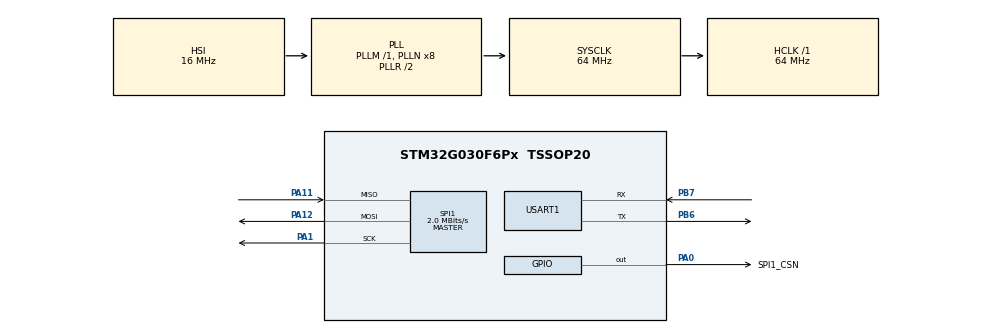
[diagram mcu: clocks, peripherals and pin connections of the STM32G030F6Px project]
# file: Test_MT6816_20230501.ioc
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Mcu.Family=STM32G0
Mcu.Name=STM32G030F6Px
Mcu.Package=TSSOP20
PA0.GPIO_Label=SPI1_CSN
PA0.Signal=GPIO_Output
PA1.Mode=Full_Duplex_Master
PA1.Signal=SPI1_SCK
PA11\ [PA9].Mode=Full_Duplex_Master
PA11\ [PA9].Signal=SPI1_MISO
PA12\ [PA10].Mode=Full_Duplex_Master
PA12\ [PA10].Signal=SPI1_MOSI
PA13.Mode=Serial_Wire
PA13.Signal=SYS_SWDIO
PA14-BOOT0.Mode=Serial_Wire
PA14-BOOT0.Signal=SYS_SWCLK
PA14-BOOT0__PA15.StandardMode=true
PB0__PB1__PB2__PA8.StandardMode=true
PB3__PB4__PB5__PB6.StandardMode=true
PB6.Mode=Asynchronous
PB6.Signal=USART1_TX
PB7.Mode=Asynchronous
PB7.Signal=USART1_RX
PB7__PB8.StandardMode=true
PC14-OSC32_IN\ (PC14)__PB9.StandardMode=true
ProjectManager.HeapSize=0x200
ProjectManager.StackSize=0x400
ProjectManager.TargetToolchain=MDK-ARM V5.32
RCC.ADCFreq_Value=64000000
RCC.AHBFreq_Value=64000000
RCC.CortexFreq_Value=64000000
RCC.EXTERNAL_CLOCK_VALUE=12288000
RCC.HCLKFreq_Value=64000000
RCC.HSE_VALUE=8000000
RCC.HSI_VALUE=16000000
RCC.LSE_VALUE=32768
RCC.SYSCLKFreq_VALUE=64000000
RCC.SYSCLKSource=RCC_SYSCLKSOURCE_PLLCLK
RCC.VCOOutputFreq_Value=128000000
SPI1.BaudRatePrescaler=SPI_BAUDRATEPRESCALER_32
SPI1.CLKPhase=SPI_PHASE_2EDGE
SPI1.CLKPolarity=SPI_POLARITY_HIGH
SPI1.CalculateBaudRate=2.0 MBits/s
SPI1.DataSize=SPI_DATASIZE_16BIT
SPI1.Direction=SPI_DIRECTION_2LINES
SPI1.Mode=SPI_MODE_MASTER
SPI1.VirtualType=VM_MASTER
TIM17.Period=999
TIM17.Prescaler=63
USART1.VirtualMode-Asynchronous=VM_ASYNC
VP_TIM17_VS_ClockSourceINT.Mode=Enable_Timer
board=custom

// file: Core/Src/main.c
/* USER CODE BEGIN Header */
/**
  ******************************************************************************
  * @file           : main.c
  * @brief          : Main program body
  ******************************************************************************
  * @attention
  *
  * Copyright (c) 2023 STMicroelectronics.
  * All rights reserved.
  *
  * This software is licensed under terms that can be found in the LICENSE file
  * in the root directory of this software component.
  * If no LICENSE file comes with this software, it is provided AS-IS.
  *
  ******************************************************************************
  */
/* USER CODE END Header */
#include "main.h"
#include "spi.h"
#include "tim.h"
#include "usart.h"
#include "gpio.h"

/* USER CODE BEGIN Includes */
#include "magnetic_sensor.h"
/* USER CODE END Includes */

void SystemClock_Config(void);

int main(void)
{
  /* USER CODE BEGIN 1 */
	Magnetic_Sensor* MS;

  /* USER CODE END 1 */

  /* MCU Configuration--------------------------------------------------------*/

  /* Reset of all peripherals, Initializes the Flash interface and the Systick. */
  HAL_Init();

  /* Configure the system clock */
  SystemClock_Config();

  /* Initialize all configured peripherals */
  MX_GPIO_Init();
  MX_SPI1_Init();
  MX_USART1_UART_Init();
  MX_TIM17_Init();
  /* USER CODE BEGIN 2 */
	MS = new_Magnetic_Sensor(SPI1, GPIOA, LL_GPIO_PIN_0);
	LL_TIM_EnableCounter(TIM17);
  /* USER CODE END 2 */

  /* Infinite loop */
  while (1)
  {

    /* USER CODE BEGIN 3 */
		MS->get(MS);
		printf("%4x %d %d\r\n", (uint16_t)MS->angle, MS->pc_flag, MS->no_mag_flag);
    HAL_Delay(100);
  }
  /* USER CODE END 3 */
}

void SystemClock_Config(void)
{
  RCC_OscInitTypeDef RCC_OscInitStruct = {0};
  RCC_ClkInitTypeDef RCC_ClkInitStruct = {0};

  /** Configure the main internal regulator output voltage
  */
  HAL_PWREx_ControlVoltageScaling(PWR_REGULATOR_VOLTAGE_SCALE1);

  /** Initializes the RCC Oscillators according to the specified parameters
  * in the RCC_OscInitTypeDef structure.
  */
  RCC_OscInitStruct.OscillatorType = RCC_OSCILLATORTYPE_HSI;
  RCC_OscInitStruct.HSIState = RCC_HSI_ON;
  RCC_OscInitStruct.HSIDiv = RCC_HSI_DIV1;
  RCC_OscInitStruct.HSICalibrationValue = RCC_HSICALIBRATION_DEFAULT;
  RCC_OscInitStruct.PLL.PLLState = RCC_PLL_ON;
  RCC_OscInitStruct.PLL.PLLSource = RCC_PLLSOURCE_HSI;
  RCC_OscInitStruct.PLL.PLLM = RCC_PLLM_DIV1;
  RCC_OscInitStruct.PLL.PLLN = 8;
  RCC_OscInitStruct.PLL.PLLP = RCC_PLLP_DIV2;
  RCC_OscInitStruct.PLL.PLLR = RCC_PLLR_DIV2;
  if (HAL_RCC_OscConfig(&RCC_OscInitStruct) != HAL_OK)
  {
    Error_Handler();
  }

  /** Initializes the CPU, AHB and APB buses clocks
  */
  RCC_ClkInitStruct.ClockType = RCC_CLOCKTYPE_HCLK|RCC_CLOCKTYPE_SYSCLK
                              |RCC_CLOCKTYPE_PCLK1;
  RCC_ClkInitStruct.SYSCLKSource = RCC_SYSCLKSOURCE_PLLCLK;
  RCC_ClkInitStruct.AHBCLKDivider = RCC_SYSCLK_DIV1;
  RCC_ClkInitStruct.APB1CLKDivider = RCC_HCLK_DIV1;

  if (HAL_RCC_ClockConfig(&RCC_ClkInitStruct, FLASH_LATENCY_2) != HAL_OK)
  {
    Error_Handler();
  }
}

void Error_Handler(void)
{
  __disable_irq();
  while (1)
  {
  }
}
